# SPG2_1.0 register map
Vendor: Texas Instruments
Peripheral module from a debugger description file (folder mspm33c321x).
Registers are 32-bit, read-write, no defined reset value unless marked. A register's access mark holds for its fields unless they carry their own. Offsets are as the file gives them; lines under a group give offsets from that group; [hi:lo] are bit positions; {n}, {i} and the like mark numbered series; 'fields as' and 'values as' point back to an identical list; <NAME> marks a mode.

## SPG2
0x1120 SPG2_UNICOMM_LPBK group
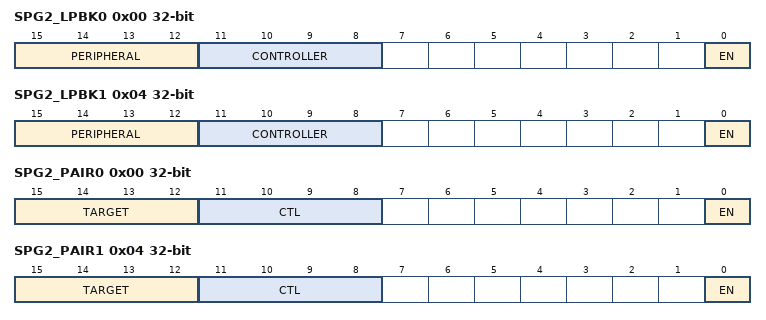
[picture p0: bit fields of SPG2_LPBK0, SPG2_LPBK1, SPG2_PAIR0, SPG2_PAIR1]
  0x00 SPG2_LPBK0 — Loopback between SPG instances User has to ensure that the SPGs looped back have the same underlying IP instantiated; i.e. both UART, both SPI, both I2C, etc.,
    [15:12] PERIPHERAL — Select SPG peripheral for loopback. Signals invovled in loopback based on interface chosen 1. SPI : CS, SCLK, SDI, SDO 2. I2C : SCL, SDA 3. UART : TX, RX
      {v}=SPG{v+1} (SPG responder select for loopback.) (v=0..15)
    [11:8] CONTROLLER — Select SPG controller for loopback. Signals invovled in loopback based on interface chosen 1. SPI : CS, SCLK, SDI, SDO 2. I2C : SCL, SDA 3. UART : TX, RX
      {v}=SPG{v+1} (SPG commander select for loopback.) (v=0..15)
    [0] EN — Loopback enable
      0=DISABLE (Does not select this clock as a source); 1=ENABLE (Select this clock as a source)
  0x04 SPG2_LPBK1 — Loopback between SPG instances User has to ensure that the SPGs looped back have the same underlying IP instantiated; i.e. both UART, both SPI, both I2C, etc.,
    fields as SPG2_UNICOMM_LPBK.SPG2_LPBK0
0x11C0 SPG2_I2C_PAIR group
  0x00 SPG2_PAIR0 — Pairing of I2C for MULTI-MASTER/SMBUS applications
    [15:12] TARGET — UNICOMM instance for loopback. This instance will be treated as the target
      {v}=SPG{v+1} (SPG responder select for loopback.) (v=0..15)
    [11:8] CTL — UNICOMM instance for loopback. This instance will be treated as the controller.
      {v}=SPG{v+1} (SPG commander select for loopback.) (v=0..15)
    [0] EN — Enable
      values as SPG2_UNICOMM_LPBK.SPG2_LPBK0.EN
  0x04 SPG2_PAIR1 — Pairing of I2C for MULTI-MASTER/SMBUS applications
    fields as SPG2_I2C_PAIR.SPG2_PAIR0
